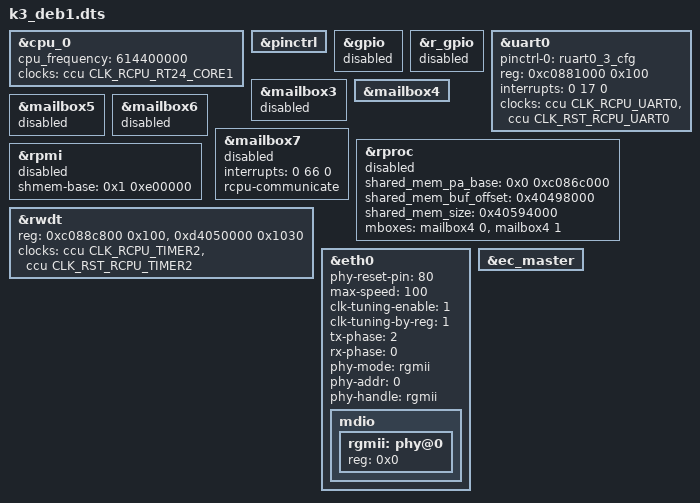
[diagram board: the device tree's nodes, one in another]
/*
 * Copyright (c) 2022-2025, Spacemit
 *
 * SPDX-License-Identifier: Apache-2.0
 */

/dts-v1/;

#include "../../k3.dtsi"
#include "../../k3-pinctrl.dtsi"

&cpu_0 {
	cpu_frequency = <614400000>;
	clocks = <&ccu CLK_RCPU_RT24_CORE1>;
};

&pinctrl {
	status = "okay";
};

&gpio {
	status = "disabled";
};

&r_gpio {
	status = "disabled";
};

&uart0 {
	pinctrl-names = "default";
	pinctrl-0 = <&ruart0_3_cfg>;
	status = "okay";
	reg = <0xc0881000 0x100>;
	interrupts = <0 17 0>;
	clocks = <&ccu CLK_RCPU_UART0>, <&ccu CLK_RST_RCPU_UART0>;
};

&mailbox3 {
	status = "disabled";
};

&mailbox4 {
	status = "okay";
};

&mailbox5 {
	status = "disabled";
};

&mailbox6 {
	status = "disabled";
};

&mailbox7 {
	interrupts = <0 66 0>;
	rcpu-communicate;
	status = "disabled";
};

&rproc {
	status = "disabled";
	shared_mem_pa_base = <0x0 0xc086c000>;
	shared_mem_buf_offset = <0x40498000>;
	shared_mem_size	= <0x40594000>;
	mboxes = <&mailbox4 0>, <&mailbox4 1>;
};

&rpmi {
	shmem-base = <0x1 0xe00000>;
	status = "disabled";
};

&rwdt {
	reg = <0xc088c800 0x100>, <0xd4050000 0x1030>;
	clocks = <&ccu CLK_RCPU_TIMER2>, <&ccu CLK_RST_RCPU_TIMER2>;
};

&eth0 {
	phy-reset-pin = <80>;
	max-speed = <100>;
	clk-tuning-enable = <1>;
	clk-tuning-by-reg = <1>;
	tx-phase = <2>;
	rx-phase = <0>;

	phy-mode = "rgmii";
	phy-addr = <0>;
	phy-handle = <&rgmii>;

	status = "okay";

	mdio {
		#address-cells = <1>;
		#size-cells = <0>;

		rgmii: phy@0 {
			reg = <0x0>;
		};
	};
};

&ec_master {
	status = "okay";
};
